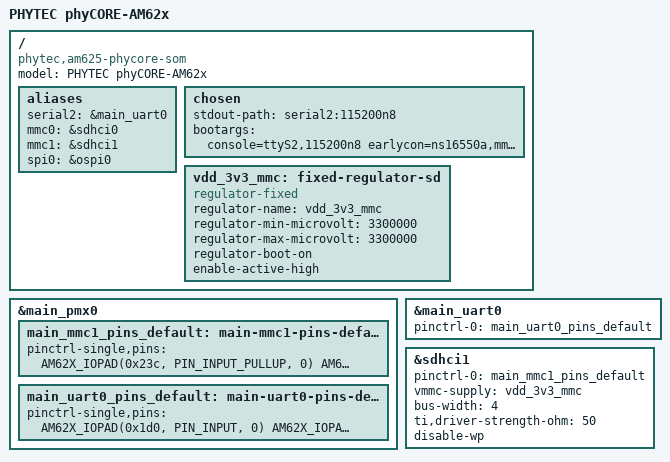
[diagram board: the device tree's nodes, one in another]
// SPDX-License-Identifier: GPL-2.0
/*
 * Copyright (C) 2022 PHYTEC Messtechnik GmbH
 * Author: Wadim Egorov <w.egorov@phytec.de>
 */

/dts-v1/;

#include "k3-am625.dtsi"
#include "k3-am62-phycore-som.dtsi"

/ {
	model = "PHYTEC phyCORE-AM62x";
	compatible = "phytec,am625-phycore-som", "ti,am625";

	aliases {
		serial2 = &main_uart0;
		mmc0 = &sdhci0;
		mmc1 = &sdhci1;
		spi0 = &ospi0;
	};

	chosen {
		stdout-path = "serial2:115200n8";
		bootargs = "console=ttyS2,115200n8 earlycon=ns16550a,mmio32,0x02800000";
	};

	vdd_3v3_mmc: fixed-regulator-sd {
		/* TPS22963C */
		compatible = "regulator-fixed";
		regulator-name = "vdd_3v3_mmc";
		regulator-min-microvolt = <3300000>;
		regulator-max-microvolt = <3300000>;
		regulator-boot-on;
		enable-active-high;
	};
};

&main_pmx0 {
	main_mmc1_pins_default: main-mmc1-pins-default {
		pinctrl-single,pins = <
			AM62X_IOPAD(0x23c, PIN_INPUT_PULLUP, 0) /* (A21) MMC1_CMD */
			AM62X_IOPAD(0x234, PIN_INPUT_PULLDOWN, 0) /* (B22) MMC1_CLK */
			AM62X_IOPAD(0x230, PIN_INPUT_PULLUP, 0) /* (A22) MMC1_DAT0 */
			AM62X_IOPAD(0x22c, PIN_INPUT_PULLUP, 0) /* (B21) MMC1_DAT1 */
			AM62X_IOPAD(0x228, PIN_INPUT_PULLUP, 0) /* (C21) MMC1_DAT2 */
			AM62X_IOPAD(0x224, PIN_INPUT_PULLUP, 0) /* (D22) MMC1_DAT3 */
			AM62X_IOPAD(0x240, PIN_INPUT_PULLUP, 0) /* (D17) MMC1_SDCD */
		>;
	};

	main_uart0_pins_default: main-uart0-pins-default {
		pinctrl-single,pins = <
			AM62X_IOPAD(0x1d0, PIN_INPUT, 0) /* (A15) UART0_CTSn */
			AM62X_IOPAD(0x1d4, PIN_OUTPUT, 0) /* (B15) UART0_RTSn */
			AM62X_IOPAD(0x1c8, PIN_INPUT, 0) /* (D14) UART0_RXD */
			AM62X_IOPAD(0x1cc, PIN_OUTPUT, 0) /* (E14) UART0_TXD */
		>;
	};
};

&main_uart0 {
	pinctrl-names = "default";
	pinctrl-0 = <&main_uart0_pins_default>;
};

&sdhci1 {
	pinctrl-names = "default";
	pinctrl-0 = <&main_mmc1_pins_default>;
	vmmc-supply = <&vdd_3v3_mmc>;
	bus-width = <4>;
	ti,driver-strength-ohm = <50>;
	disable-wp;
};
